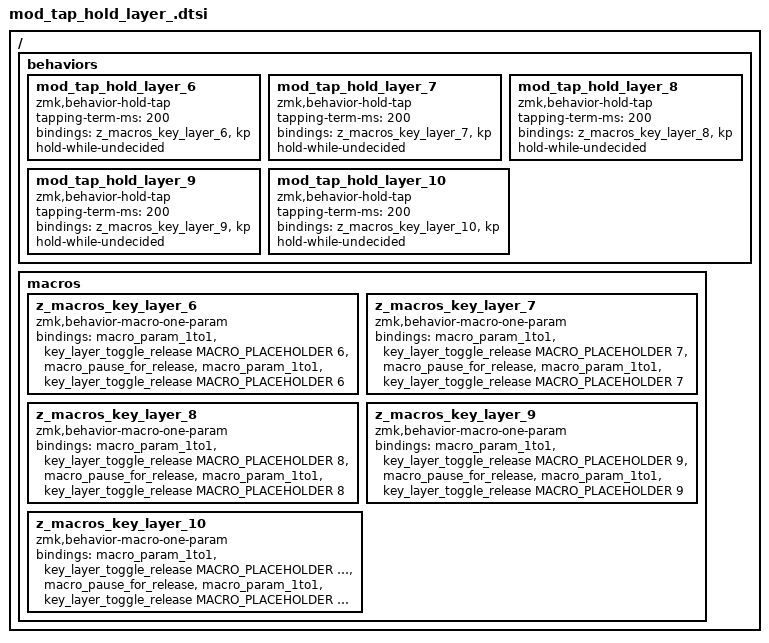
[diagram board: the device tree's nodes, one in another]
/ {
    behaviors {
        // 单击触发按键，长按触发另一个按键并换层 - 优先触发长按
        mod_tap_hold_layer_6: mod_tap_hold_layer_6 {
            compatible = "zmk,behavior-hold-tap";
            #binding-cells = <2>;
            tapping-term-ms = <200>;
            bindings = <&z_macros_key_layer_6>, <&kp>;
            hold-while-undecided;
        };
        mod_tap_hold_layer_7: mod_tap_hold_layer_7 {
            compatible = "zmk,behavior-hold-tap";
            #binding-cells = <2>;
            tapping-term-ms = <200>;
            bindings = <&z_macros_key_layer_7>, <&kp>;
            hold-while-undecided;
        };
        mod_tap_hold_layer_8: mod_tap_hold_layer_8 {
            compatible = "zmk,behavior-hold-tap";
            #binding-cells = <2>;
            tapping-term-ms = <200>;
            bindings = <&z_macros_key_layer_8>, <&kp>;
            hold-while-undecided;
        };
        mod_tap_hold_layer_9: mod_tap_hold_layer_9 {
            compatible = "zmk,behavior-hold-tap";
            #binding-cells = <2>;
            tapping-term-ms = <200>;
            bindings = <&z_macros_key_layer_9>, <&kp>;
            hold-while-undecided;
        };
        mod_tap_hold_layer_10: mod_tap_hold_layer_10 {
            compatible = "zmk,behavior-hold-tap";
            #binding-cells = <2>;
            tapping-term-ms = <200>;
            bindings = <&z_macros_key_layer_10>, <&kp>;
            hold-while-undecided;
        };
    };

    macros {
        // 同时触发按键和层 - 固定的层，配合mod_tap_hold_layer用
        z_macros_key_layer_6: z_macros_key_layer_6{
            compatible = "zmk,behavior-macro-one-param";
            #binding-cells = <1>;
            bindings = 
                <&macro_param_1to1>,
                <&key_layer_toggle_release MACRO_PLACEHOLDER 6>,
                <&macro_pause_for_release>,
                <&macro_param_1to1>,
                <&key_layer_toggle_release MACRO_PLACEHOLDER 6>;
        };
        z_macros_key_layer_7: z_macros_key_layer_7{
            compatible = "zmk,behavior-macro-one-param";
            #binding-cells = <1>;
            bindings = 
                <&macro_param_1to1>,
                <&key_layer_toggle_release MACRO_PLACEHOLDER 7>,
                <&macro_pause_for_release>,
                <&macro_param_1to1>,
                <&key_layer_toggle_release MACRO_PLACEHOLDER 7>;
        };
        z_macros_key_layer_8: z_macros_key_layer_8{
            compatible = "zmk,behavior-macro-one-param";
            #binding-cells = <1>;
            bindings = 
                <&macro_param_1to1>,
                <&key_layer_toggle_release MACRO_PLACEHOLDER 8>,
                <&macro_pause_for_release>,
                <&macro_param_1to1>,
                <&key_layer_toggle_release MACRO_PLACEHOLDER 8>;
        };
        z_macros_key_layer_9: z_macros_key_layer_9{
            compatible = "zmk,behavior-macro-one-param";
            #binding-cells = <1>;
            bindings = 
                <&macro_param_1to1>,
                <&key_layer_toggle_release MACRO_PLACEHOLDER 9>,
                <&macro_pause_for_release>,
                <&macro_param_1to1>,
                <&key_layer_toggle_release MACRO_PLACEHOLDER 9>;
        };
        z_macros_key_layer_10: z_macros_key_layer_10{
            compatible = "zmk,behavior-macro-one-param";
            #binding-cells = <1>;
            bindings = 
                <&macro_param_1to1>,
                <&key_layer_toggle_release MACRO_PLACEHOLDER 10>,
                <&macro_pause_for_release>,
                <&macro_param_1to1>,
                <&key_layer_toggle_release MACRO_PLACEHOLDER 10>;
        };
    };
};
